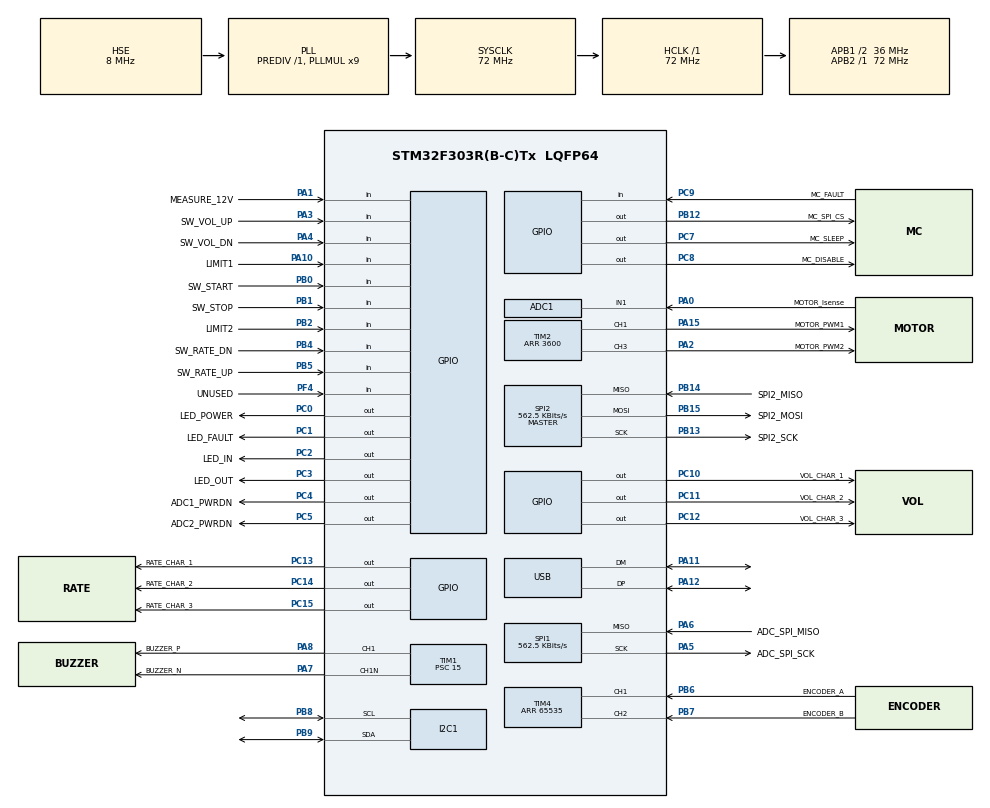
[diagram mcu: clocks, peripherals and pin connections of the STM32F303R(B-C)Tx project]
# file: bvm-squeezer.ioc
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ADC1.Channel-0\#ChannelRegularConversion=ADC_CHANNEL_1
ADC1.NbrOfConversionFlag=1
ADC1.Offset-0\#ChannelRegularConversion=0
ADC1.OffsetNumber-0\#ChannelRegularConversion=ADC_OFFSET_NONE
ADC1.Rank-0\#ChannelRegularConversion=1
ADC1.SamplingTime-0\#ChannelRegularConversion=ADC_SAMPLETIME_1CYCLE_5
ADC1.master=1
IWDG.Reload=1024
IWDG.Window=1024
Mcu.Family=STM32F3
Mcu.Name=STM32F303R(B-C)Tx
Mcu.Package=LQFP64
NVIC.PriorityGroup=NVIC_PRIORITYGROUP_4
NVIC.TIM3_IRQn=true\:0\:0\:false\:false\:true\:true\:true
NVIC.USB_LP_CAN_RX0_IRQn=true\:0\:0\:false\:false\:true\:false\:true
PA0.GPIO_Label=MOTOR_Isense
PA0.Mode=IN1-Single-Ended
PA0.Signal=ADC1_IN1
PA1.GPIO_Label=MEASURE_12V
PA1.Signal=GPIO_Input
PA10.GPIO_Label=LIMIT1
PA10.Signal=GPIO_Input
PA11.Mode=Device
PA11.Signal=USB_DM
PA12.Mode=Device
PA12.Signal=USB_DP
PA13.Signal=SYS_JTMS-SWDIO
PA14.Signal=SYS_JTCK-SWCLK
PA15.GPIO_Label=MOTOR_PWM1
PA15.Signal=S_TIM2_CH1_ETR
PA2.GPIO_Label=MOTOR_PWM2
PA2.Signal=S_TIM2_CH3
PA3.GPIO_Label=SW_VOL_UP
PA3.GPIO_PuPd=GPIO_PULLUP
PA3.Signal=GPIO_Input
PA4.GPIO_Label=SW_VOL_DN
PA4.GPIO_PuPd=GPIO_PULLUP
PA4.Signal=GPIO_Input
PA5.GPIO_Label=ADC_SPI_SCK
PA5.Mode=RX_Only_Simplex_Unidirect_Master
PA5.Signal=SPI1_SCK
PA6.GPIO_Label=ADC_SPI_MISO
PA6.Mode=RX_Only_Simplex_Unidirect_Master
PA6.Signal=SPI1_MISO
PA7.GPIO_Label=BUZZER_N
PA7.Mode=PWM Generation1 CH1 CH1N
PA7.Signal=TIM1_CH1N
PA8.GPIO_Label=BUZZER_P
PA8.Signal=S_TIM1_CH1
PB0.GPIO_Label=SW_START
PB0.GPIO_PuPd=GPIO_PULLUP
PB0.Signal=GPIO_Input
PB1.GPIO_Label=SW_STOP
PB1.GPIO_PuPd=GPIO_PULLUP
PB1.Signal=GPIO_Input
PB12.GPIO_Label=MC_SPI_CS
PB12.Signal=GPIO_Output
PB13.GPIO_Label=SPI2_SCK
PB13.Mode=Full_Duplex_Master
PB13.Signal=SPI2_SCK
PB14.GPIO_Label=SPI2_MISO
PB14.Mode=Full_Duplex_Master
PB14.Signal=SPI2_MISO
PB15.GPIO_Label=SPI2_MOSI
PB15.Mode=Full_Duplex_Master
PB15.Signal=SPI2_MOSI
PB2.GPIO_Label=LIMIT2
PB2.Signal=GPIO_Input
PB3.GPIO_Label=SWO
PB3.Mode=Trace_Asynchronous_SW
PB3.Signal=SYS_JTDO-TRACESWO
PB4.GPIO_Label=SW_RATE_DN
PB4.GPIO_PuPd=GPIO_PULLUP
PB4.Signal=GPIO_Input
PB5.GPIO_Label=SW_RATE_UP
PB5.GPIO_PuPd=GPIO_PULLUP
PB5.Signal=GPIO_Input
PB6.GPIO_Label=ENCODER_A
PB6.Signal=S_TIM4_CH1
PB7.GPIO_Label=ENCODER_B
PB7.Signal=S_TIM4_CH2
PB8.Mode=I2C
PB8.Signal=I2C1_SCL
PB9.Mode=I2C
PB9.Signal=I2C1_SDA
PC0.GPIO_Label=LED_POWER
PC0.Signal=GPIO_Output
PC1.GPIO_Label=LED_FAULT
PC1.Signal=GPIO_Output
PC10.GPIO_Label=VOL_CHAR_1
PC10.Signal=GPIO_Output
PC11.GPIO_Label=VOL_CHAR_2
PC11.Signal=GPIO_Output
PC12.GPIO_Label=VOL_CHAR_3
PC12.Signal=GPIO_Output
PC13.GPIO_Label=RATE_CHAR_1
PC13.Signal=GPIO_Output
PC14-OSC32_IN.GPIO_Label=RATE_CHAR_2
PC14-OSC32_IN.Signal=GPIO_Output
PC15-OSC32_OUT.GPIO_Label=RATE_CHAR_3
PC15-OSC32_OUT.Signal=GPIO_Output
PC2.GPIO_Label=LED_IN
PC2.Signal=GPIO_Output
PC3.GPIO_Label=LED_OUT
PC3.Signal=GPIO_Output
PC4.GPIO_Label=ADC1_PWRDN
PC4.Signal=GPIO_Output
PC5.GPIO_Label=ADC2_PWRDN
PC5.Signal=GPIO_Output
PC7.GPIO_Label=MC_SLEEP
PC7.Signal=GPIO_Output
PC8.GPIO_Label=MC_DISABLE
PC8.Signal=GPIO_Output
PC9.GPIO_Label=MC_FAULT
PC9.Signal=GPIO_Input
PF0-OSC_IN.Mode=HSE-External-Oscillator
PF0-OSC_IN.Signal=RCC_OSC_IN
PF1-OSC_OUT.Mode=HSE-External-Oscillator
PF1-OSC_OUT.Signal=RCC_OSC_OUT
PF4.GPIO_Label=UNUSED
PF4.Signal=GPIO_Input
ProjectManager.HeapSize=0x200
ProjectManager.StackSize=0x400
ProjectManager.TargetToolchain=Other Toolchains (GPDSC)
RCC.AHBFreq_Value=72000000
RCC.APB1CLKDivider=RCC_HCLK_DIV2
RCC.APB1Freq_Value=36000000
RCC.APB1TimFreq_Value=72000000
RCC.APB2Freq_Value=72000000
RCC.APB2TimFreq_Value=72000000
RCC.CortexFreq_Value=72000000
RCC.HCLKFreq_Value=72000000
RCC.HSE_VALUE=8000000
RCC.HSI_VALUE=8000000
RCC.LSE_VALUE=32768
RCC.PLLMUL=RCC_PLL_MUL9
RCC.PRESCALERUSB=RCC_USBCLKSOURCE_PLL_DIV1_5
RCC.SYSCLKFreq_VALUE=72000000
RCC.SYSCLKSourceVirtual=RCC_SYSCLKSOURCE_PLLCLK
RCC.USBFreq_Value=48000000
SH.S_TIM1_CH1.0=TIM1_CH1,PWM Generation1 CH1 CH1N
SH.S_TIM2_CH1_ETR.0=TIM2_CH1,PWM Generation1 CH1
SH.S_TIM2_CH3.0=TIM2_CH3,PWM Generation3 CH3
SH.S_TIM4_CH1.0=TIM4_CH1,Encoder_Interface
SH.S_TIM4_CH2.0=TIM4_CH2,Encoder_Interface
SPI1.BaudRatePrescaler=SPI_BAUDRATEPRESCALER_128
SPI1.CLKPhase=SPI_PHASE_2EDGE
SPI1.CalculateBaudRate=562.5 KBits/s
SPI1.DataSize=SPI_DATASIZE_8BIT
SPI1.Direction=SPI_DIRECTION_2LINES_RXONLY
SPI1.Mode=SPI_MODE_MASTER
SPI1.VirtualType=VM_MASTER
SPI2.BaudRatePrescaler=SPI_BAUDRATEPRESCALER_64
SPI2.CLKPhase=SPI_PHASE_2EDGE
SPI2.CalculateBaudRate=562.5 KBits/s
SPI2.DataSize=SPI_DATASIZE_8BIT
SPI2.Direction=SPI_DIRECTION_2LINES
SPI2.Mode=SPI_MODE_MASTER
SPI2.VirtualType=VM_MASTER
TIM1.Channel-PWM\ Generation1\ CH1\ CH1N=TIM_CHANNEL_1
TIM1.DeadTime=200
TIM1.Period=1074
TIM1.Prescaler=15
TIM1.Pulse-PWM\ Generation1\ CH1\ CH1N=537
TIM2.Channel-PWM\ Generation1\ CH1=TIM_CHANNEL_1
TIM2.Channel-PWM\ Generation3\ CH3=TIM_CHANNEL_3
TIM2.Period=3600
TIM3.Period=10
TIM3.Prescaler=71
TIM4.AutoReloadPreload=TIM_AUTORELOAD_PRELOAD_ENABLE
TIM4.EncoderMode=TIM_ENCODERMODE_TI1
TIM4.Period=65535
USB_DEVICE.CLASS_NAME_FS=CDC
USB_DEVICE.CONFIGURATION_STRING_CDC_FS=ABVM Config
USB_DEVICE.INTERFACE_STRING_CDC_FS=ABVM Interface
USB_DEVICE.MANUFACTURER_STRING=autoVENT.org
USB_DEVICE.PRODUCT_STRING_CDC_FS=ABVM
USB_DEVICE.VirtualMode=Cdc
USB_DEVICE.VirtualModeFS=Cdc_FS
VP_IWDG_VS_IWDG.Mode=IWDG_Activate
VP_TIM3_VS_ClockSourceINT.Mode=Internal
VP_USB_DEVICE_VS_USB_DEVICE_CDC_FS.Mode=CDC_FS
board=custom

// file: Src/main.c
/* USER CODE BEGIN Header */
/**
  ******************************************************************************
  * @file           : main.c
  * @brief          : Main program body
  ******************************************************************************
  * @attention
  *
  * <h2><center>&copy; Copyright (c) 2020 STMicroelectronics.
  * All rights reserved.</center></h2>
  *
  * This software component is licensed by ST under BSD 3-Clause license,
  * the "License"; You may not use this file except in compliance with the
  * License. You may obtain a copy of the License at:
  *                        opensource.org/licenses/BSD-3-Clause
  *
  ******************************************************************************
  */
/* USER CODE END Header */

#include "main.h"
#include "adc.h"
#include "i2c.h"
#include "iwdg.h"
#include "spi.h"
#include "tim.h"
#include "usb_device.h"
#include "gpio.h"

/* USER CODE BEGIN Includes */

#include "abvm.h"

/* USER CODE END Includes */

void SystemClock_Config(void);

int main(void)
{

  /* MCU Configuration--------------------------------------------------------*/

  /* Reset of all peripherals, Initializes the Flash interface and the Systick. */
  HAL_Init();

  /* Configure the system clock */
  SystemClock_Config();

  /* Initialize all configured peripherals */
  MX_GPIO_Init();
  MX_ADC1_Init();
  MX_I2C1_Init();
  MX_SPI1_Init();
  MX_SPI2_Init();
  MX_USB_DEVICE_Init();
  MX_TIM1_Init();
  MX_TIM2_Init();
  MX_TIM3_Init();
  MX_TIM4_Init();
  MX_IWDG_Init();
  /* USER CODE BEGIN 2 */
  HAL_ADC_Start(&hadc1);

  abvm_init();

  /* USER CODE END 2 */

  /* Infinite loop */
  while (1)
  {

    /* USER CODE BEGIN 3 */
    abvm_update();
  }
  /* USER CODE END 3 */
}

void SystemClock_Config(void)
{
  RCC_OscInitTypeDef RCC_OscInitStruct = {0};
  RCC_ClkInitTypeDef RCC_ClkInitStruct = {0};
  RCC_PeriphCLKInitTypeDef PeriphClkInit = {0};

  /** Initializes the CPU, AHB and APB busses clocks
  */
  RCC_OscInitStruct.OscillatorType = RCC_OSCILLATORTYPE_HSI|RCC_OSCILLATORTYPE_LSI
                              |RCC_OSCILLATORTYPE_HSE;
  RCC_OscInitStruct.HSEState = RCC_HSE_ON;
  RCC_OscInitStruct.HSEPredivValue = RCC_HSE_PREDIV_DIV1;
  RCC_OscInitStruct.HSIState = RCC_HSI_ON;
  RCC_OscInitStruct.HSICalibrationValue = RCC_HSICALIBRATION_DEFAULT;
  RCC_OscInitStruct.LSIState = RCC_LSI_ON;
  RCC_OscInitStruct.PLL.PLLState = RCC_PLL_ON;
  RCC_OscInitStruct.PLL.PLLSource = RCC_PLLSOURCE_HSE;
  RCC_OscInitStruct.PLL.PLLMUL = RCC_PLL_MUL9;
  if (HAL_RCC_OscConfig(&RCC_OscInitStruct) != HAL_OK)
  {
    Error_Handler();
  }
  /** Initializes the CPU, AHB and APB busses clocks
  */
  RCC_ClkInitStruct.ClockType = RCC_CLOCKTYPE_HCLK|RCC_CLOCKTYPE_SYSCLK
                              |RCC_CLOCKTYPE_PCLK1|RCC_CLOCKTYPE_PCLK2;
  RCC_ClkInitStruct.SYSCLKSource = RCC_SYSCLKSOURCE_PLLCLK;
  RCC_ClkInitStruct.AHBCLKDivider = RCC_SYSCLK_DIV1;
  RCC_ClkInitStruct.APB1CLKDivider = RCC_HCLK_DIV2;
  RCC_ClkInitStruct.APB2CLKDivider = RCC_HCLK_DIV1;

  if (HAL_RCC_ClockConfig(&RCC_ClkInitStruct, FLASH_LATENCY_2) != HAL_OK)
  {
    Error_Handler();
  }
  PeriphClkInit.PeriphClockSelection = RCC_PERIPHCLK_USB|RCC_PERIPHCLK_I2C1
                              |RCC_PERIPHCLK_TIM1|RCC_PERIPHCLK_ADC12;
  PeriphClkInit.Adc12ClockSelection = RCC_ADC12PLLCLK_DIV1;
  PeriphClkInit.I2c1ClockSelection = RCC_I2C1CLKSOURCE_HSI;
  PeriphClkInit.USBClockSelection = RCC_USBCLKSOURCE_PLL_DIV1_5;
  PeriphClkInit.Tim1ClockSelection = RCC_TIM1CLK_HCLK;
  if (HAL_RCCEx_PeriphCLKConfig(&PeriphClkInit) != HAL_OK)
  {
    Error_Handler();
  }
}

void Error_Handler(void)
{
}

/************************ (C) COPYRIGHT STMicroelectronics *****END OF FILE****/
